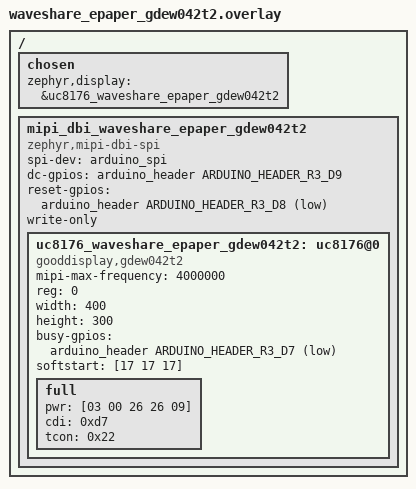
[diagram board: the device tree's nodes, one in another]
/*
 * Copyright (c) 2021, Linumiz
 *
 */

#include "waveshare_epaper_common.dtsi"
#include <zephyr/dt-bindings/gpio/arduino-header-r3.h>

/ {
	chosen {
		zephyr,display = &uc8176_waveshare_epaper_gdew042t2;
	};

	mipi_dbi_waveshare_epaper_gdew042t2 {
		compatible = "zephyr,mipi-dbi-spi";
		spi-dev = <&arduino_spi>;
		dc-gpios = <&arduino_header ARDUINO_HEADER_R3_D9 GPIO_ACTIVE_HIGH>;
		reset-gpios = <&arduino_header ARDUINO_HEADER_R3_D8 GPIO_ACTIVE_LOW>;
		write-only;
		#address-cells = <1>;
		#size-cells = <0>;

		uc8176_waveshare_epaper_gdew042t2: uc8176@0 {
			compatible = "gooddisplay,gdew042t2", "ultrachip,uc8176";
			mipi-max-frequency = <4000000>;
			reg = <0>;
			width = <400>;
			height = <300>;
			busy-gpios = <&arduino_header ARDUINO_HEADER_R3_D7 GPIO_ACTIVE_LOW>;

			softstart = [17 17 17];

			full {
				pwr = [03 00 26 26 09];
				cdi = <0xd7>;
				tcon = <0x22>;
			};
		};
	};
};
